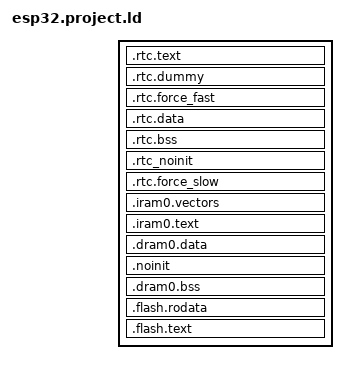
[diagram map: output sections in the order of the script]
/* Automatically generated file; DO NOT EDIT */
/* Espressif IoT Development Framework Linker Script */
/* Generated from: C:/msys32/home/adewa/esp32/esp-idf/components/esp32/ld/esp32.project.ld.in */

/*  Default entry point:  */
ENTRY(call_start_cpu0);

SECTIONS
{
  /* RTC fast memory holds RTC wake stub code,
     including from any source file named rtc_wake_stub*.c
  */
  .rtc.text :
  {
    . = ALIGN(4);

    *( .rtc.literal  .rtc.text  .rtc.text.*)

    *rtc_wake_stub*.*(.literal .text .literal.* .text.*)
    _rtc_text_end = ABSOLUTE(.);
  } > rtc_iram_seg
  
  /*
    This section is required to skip rtc.text area because rtc_iram_seg and 
    rtc_data_seg are reflect the same address space on different buses.
  */
  .rtc.dummy :
  {
    _rtc_dummy_start = ABSOLUTE(.);
    _rtc_fast_start = ABSOLUTE(.);
    . = SIZEOF(.rtc.text);
    _rtc_dummy_end = ABSOLUTE(.);
  } > rtc_data_seg

  /* This section located in RTC FAST Memory area. 
     It holds data marked with RTC_FAST_ATTR attribute. 
     See the file "esp_attr.h" for more information.
  */
  .rtc.force_fast :
  {
    . = ALIGN(4);
    _rtc_force_fast_start = ABSOLUTE(.);
    *(.rtc.force_fast .rtc.force_fast.*)
    . = ALIGN(4) ;
    _rtc_force_fast_end = ABSOLUTE(.);
  } > rtc_data_seg

  /* RTC data section holds RTC wake stub
     data/rodata, including from any source file
     named rtc_wake_stub*.c and the data marked with
     RTC_DATA_ATTR, RTC_RODATA_ATTR attributes.
     The memory location of the data is dependent on 
     CONFIG_ESP32_RTCDATA_IN_FAST_MEM option.
  */
  .rtc.data :
  {
    _rtc_data_start = ABSOLUTE(.);

    *( .rtc.data  .rtc.data.*  .rtc.rodata  .rtc.rodata.*)

    *rtc_wake_stub*.*(.data .rodata .data.* .rodata.* .bss .bss.*)
    _rtc_data_end = ABSOLUTE(.);
  } > rtc_data_location

  /* RTC bss, from any source file named rtc_wake_stub*.c */
  .rtc.bss (NOLOAD) :
  {
    _rtc_bss_start = ABSOLUTE(.);
    *rtc_wake_stub*.*(.bss .bss.*)
    *rtc_wake_stub*.*(COMMON)

    *( .rtc.bss)

    _rtc_bss_end = ABSOLUTE(.);
  } > rtc_data_location

  /* This section holds data that should not be initialized at power up 
     and will be retained during deep sleep.
     User data marked with RTC_NOINIT_ATTR will be placed
     into this section. See the file "esp_attr.h" for more information. 
	 The memory location of the data is dependent on 
     CONFIG_ESP32_RTCDATA_IN_FAST_MEM option.
  */
  .rtc_noinit (NOLOAD):
  {
    . = ALIGN(4);
    _rtc_noinit_start = ABSOLUTE(.);
    *(.rtc_noinit .rtc_noinit.*)
    . = ALIGN(4) ;
    _rtc_noinit_end = ABSOLUTE(.);
  } > rtc_data_location

  /* This section located in RTC SLOW Memory area. 
     It holds data marked with RTC_SLOW_ATTR attribute. 
     See the file "esp_attr.h" for more information.
  */
  .rtc.force_slow :
  {
    . = ALIGN(4);
    _rtc_force_slow_start = ABSOLUTE(.);
    *(.rtc.force_slow .rtc.force_slow.*)
    . = ALIGN(4) ;
    _rtc_force_slow_end = ABSOLUTE(.);
  } > rtc_slow_seg

  /* Get size of rtc slow data based on rtc_data_location alias */
  _rtc_slow_length = (ORIGIN(rtc_slow_seg) == ORIGIN(rtc_data_location)) 
                        ? (_rtc_force_slow_end - _rtc_data_start) 
                        : (_rtc_force_slow_end - _rtc_force_slow_start);

  _rtc_fast_length = (ORIGIN(rtc_slow_seg) == ORIGIN(rtc_data_location)) 
                        ? (_rtc_force_fast_end - _rtc_fast_start) 
                        : (_rtc_noinit_end - _rtc_fast_start);
  
  ASSERT((_rtc_slow_length <= LENGTH(rtc_slow_seg)),
          "RTC_SLOW segment data does not fit.")
          
  ASSERT((_rtc_fast_length <= LENGTH(rtc_data_seg)),
          "RTC_FAST segment data does not fit.")

  /* Send .iram0 code to iram */
  .iram0.vectors :
  {
    _iram_start = ABSOLUTE(.);
    /* Vectors go to IRAM */
    _init_start = ABSOLUTE(.);
    /* Vectors according to builds/RF-2015.2-win32/esp108_v1_2_s5_512int_2/config.html */
    . = 0x0;
    KEEP(*(.WindowVectors.text));
    . = 0x180;
    KEEP(*(.Level2InterruptVector.text));
    . = 0x1c0;
    KEEP(*(.Level3InterruptVector.text));
    . = 0x200;
    KEEP(*(.Level4InterruptVector.text));
    . = 0x240;
    KEEP(*(.Level5InterruptVector.text));
    . = 0x280;
    KEEP(*(.DebugExceptionVector.text));
    . = 0x2c0;
    KEEP(*(.NMIExceptionVector.text));
    . = 0x300;
    KEEP(*(.KernelExceptionVector.text));
    . = 0x340;
    KEEP(*(.UserExceptionVector.text));
    . = 0x3C0;
    KEEP(*(.DoubleExceptionVector.text));
    . = 0x400;
    *(.*Vector.literal)

    *(.UserEnter.literal);
    *(.UserEnter.text);
    . = ALIGN (16);
    *(.entry.text)
    *(.init.literal)
    *(.init)
    _init_end = ABSOLUTE(.);
  } > iram0_0_seg

  .iram0.text :
  {
    /* Code marked as runnning out of IRAM */
    _iram_text_start = ABSOLUTE(.);

    *( .iram1  .iram1.*)
    *libapp_trace.a:( .literal  .literal.*  .text  .text.*)
    *libesp32.a:panic.*( .literal  .literal.*  .text  .text.*)
    *libesp_ringbuf.a:( .literal  .literal.*  .text  .text.*)
    *libespcoredump.a:core_dump_common.*( .literal  .literal.*  .text  .text.*)
    *libespcoredump.a:core_dump_flash.*( .literal  .literal.*  .text  .text.*)
    *libespcoredump.a:core_dump_port.*( .literal  .literal.*  .text  .text.*)
    *libespcoredump.a:core_dump_uart.*( .literal  .literal.*  .text  .text.*)
    *libfreertos.a:( .literal  .literal.*  .text  .text.*)
    *libgcc.a:lib2funcs.*( .literal  .literal.*  .text  .text.*)
    *libgcov.a:( .literal  .literal.*  .text  .text.*)
    *libhal.a:( .literal  .literal.*  .text  .text.*)
    *libheap.a:multi_heap.*( .literal  .literal.*  .text  .text.*)
    *libheap.a:multi_heap_poisoning.*( .literal  .literal.*  .text  .text.*)
    *libnet80211.a:( .wifi0iram  .wifi0iram.*)
    *libnet80211.a:( .wifirxiram  .wifirxiram.*)
    *libpp.a:( .wifi0iram  .wifi0iram.*)
    *libpp.a:( .wifirxiram  .wifirxiram.*)
    *librtc.a:( .literal  .literal.*  .text  .text.*)
    *libsoc.a:cpu_util.*( .literal  .literal.*  .text  .text.*)
    *libsoc.a:rtc_clk.*( .literal  .literal.*  .text  .text.*)
    *libsoc.a:rtc_clk_init.*( .literal  .literal.*  .text  .text.*)
    *libsoc.a:rtc_init.*( .literal  .literal.*  .text  .text.*)
    *libsoc.a:rtc_periph.*( .literal  .literal.*  .text  .text.*)
    *libsoc.a:rtc_pm.*( .literal  .literal.*  .text  .text.*)
    *libsoc.a:rtc_sleep.*( .literal  .literal.*  .text  .text.*)
    *libsoc.a:rtc_time.*( .literal  .literal.*  .text  .text.*)
    *libsoc.a:rtc_wdt.*( .literal  .literal.*  .text  .text.*)
    *libspi_flash.a:spi_flash_rom_patch.*( .literal  .literal.*  .text  .text.*)
    *libxtensa-debug-module.a:eri.*( .literal  .literal.*  .text  .text.*)

    _iram_text_end = ABSOLUTE(.);
    _iram_end = ABSOLUTE(.);
  } > iram0_0_seg

  ASSERT(((_iram_text_end - ORIGIN(iram0_0_seg)) <= LENGTH(iram0_0_seg)),
          "IRAM0 segment data does not fit.")

  .dram0.data :
  {
    _data_start = ABSOLUTE(.);
    _bt_data_start = ABSOLUTE(.);
    *libbt.a:(.data .data.*)
    . = ALIGN (4);
    _bt_data_end = ABSOLUTE(.);
    _btdm_data_start = ABSOLUTE(.);
    *libbtdm_app.a:(.data .data.*)
    . = ALIGN (4);
    _btdm_data_end = ABSOLUTE(.);
    *(.gnu.linkonce.d.*)
    *(.data1)
    *(.sdata)
    *(.sdata.*)
    *(.gnu.linkonce.s.*)
    *(.sdata2)
    *(.sdata2.*)
    *(.gnu.linkonce.s2.*)
    *(.jcr)

    *( .data  .data.*  .dram1  .dram1.*)
    *libapp_trace.a:( .rodata  .rodata.*)
    *libesp32.a:panic.*( .rodata  .rodata.*)
    *libgcov.a:( .rodata  .rodata.*)
    *libheap.a:multi_heap.*( .rodata  .rodata.*)
    *libheap.a:multi_heap_poisoning.*( .rodata  .rodata.*)
    *libphy.a:( .rodata  .rodata.*)
    *libsoc.a:rtc_clk.*( .rodata  .rodata.*)

    _data_end = ABSOLUTE(.);
    . = ALIGN(4);
  } > dram0_0_seg

  /*This section holds data that should not be initialized at power up.
    The section located in Internal SRAM memory region. The macro _NOINIT
    can be used as attribute to place data into this section.
    See the esp_attr.h file for more information.
  */
  .noinit (NOLOAD):
  {
    . = ALIGN(4);
    _noinit_start = ABSOLUTE(.);
    *(.noinit .noinit.*) 
    . = ALIGN(4) ;
    _noinit_end = ABSOLUTE(.);
  } > dram0_0_seg

  /* Shared RAM */
  .dram0.bss (NOLOAD) :
  {
    . = ALIGN (8);
    _bss_start = ABSOLUTE(.);
    *(.ext_ram.bss*)
    _bt_bss_start = ABSOLUTE(.);
    *libbt.a:(.bss .bss.* COMMON)
    . = ALIGN (4);
    _bt_bss_end = ABSOLUTE(.);
    _btdm_bss_start = ABSOLUTE(.);
    *libbtdm_app.a:(.bss .bss.* COMMON)
    . = ALIGN (4);
    _btdm_bss_end = ABSOLUTE(.);

    *( .bss  .bss.*  COMMON)

    *(.dynsbss)
    *(.sbss)
    *(.sbss.*)
    *(.gnu.linkonce.sb.*)
    *(.scommon)
    *(.sbss2)
    *(.sbss2.*)
    *(.gnu.linkonce.sb2.*)
    *(.dynbss)
    *(.share.mem)
    *(.gnu.linkonce.b.*)

    . = ALIGN (8);
    _bss_end = ABSOLUTE(.);
    /* The heap starts right after end of this section */
    _heap_start = ABSOLUTE(.);
  } > dram0_0_seg

  ASSERT(((_bss_end - ORIGIN(dram0_0_seg)) <= LENGTH(dram0_0_seg)),
          "DRAM segment data does not fit.")
          
  .flash.rodata :
  {
    _rodata_start = ABSOLUTE(.);

    *(.rodata_desc .rodata_desc.*)               /* Should be the first.  App version info.        DO NOT PUT ANYTHING BEFORE IT! */
    *(.rodata_custom_desc .rodata_custom_desc.*) /* Should be the second. Custom app version info. DO NOT PUT ANYTHING BEFORE IT! */

    *(EXCLUDE_FILE(*libapp_trace.a *libesp32.a:panic.* *libphy.a *libgcov.a *libheap.a:multi_heap.* *libheap.a:multi_heap_poisoning.* *libsoc.a:rtc_clk.*) .rodata EXCLUDE_FILE(*libapp_trace.a *libesp32.a:panic.* *libphy.a *libgcov.a *libheap.a:multi_heap.* *libheap.a:multi_heap_poisoning.* *libsoc.a:rtc_clk.*) .rodata.*)

    *(.irom1.text) /* catch stray ICACHE_RODATA_ATTR */
    *(.gnu.linkonce.r.*)
    *(.rodata1)
    __XT_EXCEPTION_TABLE_ = ABSOLUTE(.);
    *(.xt_except_table)
    *(.gcc_except_table .gcc_except_table.*)
    *(.gnu.linkonce.e.*)
    *(.gnu.version_r)
    . = (. + 3) & ~ 3;
    __eh_frame = ABSOLUTE(.);
    KEEP(*(.eh_frame))
    . = (. + 7) & ~ 3;
    /*  C++ constructor and destructor tables, properly ordered:  */
    __init_array_start = ABSOLUTE(.);
    KEEP (*crtbegin.*(.ctors))
    KEEP (*(EXCLUDE_FILE (*crtend.*) .ctors))
    KEEP (*(SORT(.ctors.*)))
    KEEP (*(.ctors))
    __init_array_end = ABSOLUTE(.);
    KEEP (*crtbegin.*(.dtors))
    KEEP (*(EXCLUDE_FILE (*crtend.*) .dtors))
    KEEP (*(SORT(.dtors.*)))
    KEEP (*(.dtors))
    /*  C++ exception handlers table:  */
    __XT_EXCEPTION_DESCS_ = ABSOLUTE(.);
    *(.xt_except_desc)
    *(.gnu.linkonce.h.*)
    __XT_EXCEPTION_DESCS_END__ = ABSOLUTE(.);
    *(.xt_except_desc_end)
    *(.dynamic)
    *(.gnu.version_d)
    /* Addresses of memory regions reserved via
       SOC_RESERVE_MEMORY_REGION() */
    soc_reserved_memory_region_start = ABSOLUTE(.);
    KEEP (*(.reserved_memory_address))
    soc_reserved_memory_region_end = ABSOLUTE(.);
    _rodata_end = ABSOLUTE(.);
    /* Literals are also RO data. */
    _lit4_start = ABSOLUTE(.);
    *(*.lit4)
    *(.lit4.*)
    *(.gnu.linkonce.lit4.*)
    _lit4_end = ABSOLUTE(.);
    . = ALIGN(4);
    _thread_local_start = ABSOLUTE(.);
    *(.tdata)
    *(.tdata.*)
    *(.tbss)
    *(.tbss.*)
    _thread_local_end = ABSOLUTE(.);
    . = ALIGN(4);
  } >drom0_0_seg

  .flash.text :
  {
    _stext = .;
    _text_start = ABSOLUTE(.);

    *(EXCLUDE_FILE(*libapp_trace.a *libesp32.a:panic.* *libhal.a *librtc.a *libgcc.a:lib2funcs.* *libgcov.a *libesp_ringbuf.a *libespcoredump.a:core_dump_common.* *libespcoredump.a:core_dump_uart.* *libespcoredump.a:core_dump_flash.* *libespcoredump.a:core_dump_port.* *libfreertos.a *libheap.a:multi_heap.* *libheap.a:multi_heap_poisoning.* *libsoc.a:rtc_time.* *libsoc.a:rtc_init.* *libsoc.a:rtc_wdt.* *libsoc.a:rtc_clk_init.* *libsoc.a:rtc_sleep.* *libsoc.a:rtc_pm.* *libsoc.a:rtc_clk.* *libsoc.a:cpu_util.* *libsoc.a:rtc_periph.* *libspi_flash.a:spi_flash_rom_patch.* *libxtensa-debug-module.a:eri.*) .literal EXCLUDE_FILE(*libapp_trace.a *libesp32.a:panic.* *libhal.a *librtc.a *libgcc.a:lib2funcs.* *libgcov.a *libesp_ringbuf.a *libespcoredump.a:core_dump_common.* *libespcoredump.a:core_dump_uart.* *libespcoredump.a:core_dump_flash.* *libespcoredump.a:core_dump_port.* *libfreertos.a *libheap.a:multi_heap.* *libheap.a:multi_heap_poisoning.* *libsoc.a:rtc_time.* *libsoc.a:rtc_init.* *libsoc.a:rtc_wdt.* *libsoc.a:rtc_clk_init.* *libsoc.a:rtc_sleep.* *libsoc.a:rtc_pm.* *libsoc.a:rtc_clk.* *libsoc.a:cpu_util.* *libsoc.a:rtc_periph.* *libspi_flash.a:spi_flash_rom_patch.* *libxtensa-debug-module.a:eri.*) .literal.* EXCLUDE_FILE(*libapp_trace.a *libesp32.a:panic.* *libhal.a *librtc.a *libgcc.a:lib2funcs.* *libgcov.a *libesp_ringbuf.a *libespcoredump.a:core_dump_common.* *libespcoredump.a:core_dump_uart.* *libespcoredump.a:core_dump_flash.* *libespcoredump.a:core_dump_port.* *libfreertos.a *libheap.a:multi_heap.* *libheap.a:multi_heap_poisoning.* *libsoc.a:rtc_time.* *libsoc.a:rtc_init.* *libsoc.a:rtc_wdt.* *libsoc.a:rtc_clk_init.* *libsoc.a:rtc_sleep.* *libsoc.a:rtc_pm.* *libsoc.a:rtc_clk.* *libsoc.a:cpu_util.* *libsoc.a:rtc_periph.* *libspi_flash.a:spi_flash_rom_patch.* *libxtensa-debug-module.a:eri.*) .text EXCLUDE_FILE(*libapp_trace.a *libesp32.a:panic.* *libhal.a *librtc.a *libgcc.a:lib2funcs.* *libgcov.a *libesp_ringbuf.a *libespcoredump.a:core_dump_common.* *libespcoredump.a:core_dump_uart.* *libespcoredump.a:core_dump_flash.* *libespcoredump.a:core_dump_port.* *libfreertos.a *libheap.a:multi_heap.* *libheap.a:multi_heap_poisoning.* *libsoc.a:rtc_time.* *libsoc.a:rtc_init.* *libsoc.a:rtc_wdt.* *libsoc.a:rtc_clk_init.* *libsoc.a:rtc_sleep.* *libsoc.a:rtc_pm.* *libsoc.a:rtc_clk.* *libsoc.a:cpu_util.* *libsoc.a:rtc_periph.* *libspi_flash.a:spi_flash_rom_patch.* *libxtensa-debug-module.a:eri.*) .text.* EXCLUDE_FILE(*libpp.a *libnet80211.a) .wifi0iram EXCLUDE_FILE(*libpp.a *libnet80211.a) .wifi0iram.* EXCLUDE_FILE(*libpp.a *libnet80211.a) .wifirxiram EXCLUDE_FILE(*libpp.a *libnet80211.a) .wifirxiram.*)

    *(.stub .gnu.warning .gnu.linkonce.literal.* .gnu.linkonce.t.*.literal .gnu.linkonce.t.*)
    *(.irom0.text) /* catch stray ICACHE_RODATA_ATTR */
    *(.fini.literal)
    *(.fini)
    *(.gnu.version)
    _text_end = ABSOLUTE(.);
    _etext = .;

    /* Similar to _iram_start, this symbol goes here so it is
       resolved by addr2line in preference to the first symbol in
       the flash.text segment.
    */
    _flash_cache_start = ABSOLUTE(0);
  } >iram0_2_seg
}
